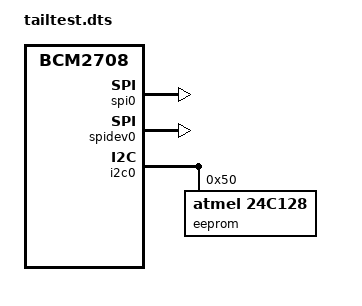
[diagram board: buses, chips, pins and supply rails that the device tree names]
/* -*- c -*-
 *
 * Device Tree Overlay for Tail production tester adapter
 *
 * This is intended to be placed within the ID EEPROM of the
 * production tester adapter.
 *
 */

/dts-v1/;
/plugin/;

/ {
	compatible = "brcm,bcm2708";

	/* Remove SPI CE1 from SPI0 CS pins */
	fragment@0 {
		target = <&spi0_cs_pins>;
		__overlay__ {
			brcm,pins = <8>;
		};
	};

	/* Enable SPI0 controller and limit to CE0 */
	fragment@1 {
		target = <&spi0>;
		__overlay__ {
			cs-gpios = <&gpio 8 1>;
			status = "okay";
		};
	};

	/* Enable generic SPI device for SPI0 CE0 */
	fragment@2 {
		target = <&spidev0>;
		__overlay__ {
			status = "okay";
		};
	};

	/* Disable generic SPI device for SPI0 CE1 */
	fragment@3 {
		target = <&spidev1>;
		__overlay__ {
			status = "disabled";
		};
	};

	/* Enable I2C0 controller and adapter's own ID EEPROM */
	fragment@4 {
		target = <&i2c0>;
		__overlay__ {
			#address-cells = <1>;
			#size-cells = <0>;

			status = "okay";

			eeprom@50 {
				compatible = "atmel,24c128";
				reg = <0x50>;
			};
		};
	};
};
